# ATmega64A register map
Vendor: Atmel; File version: 1.0
CPU: other r0p0, little endian, no MPU, no FPU, 4 interrupt priority bits
Registers are 8-bit, read-write, reset 0x0 unless marked. A register's access mark holds for its fields unless they carry their own. Offsets are from the block's base; lines under a group give offsets from that group; [hi:lo] are bit positions; {n}, {i} and the like mark numbered series; 'fields as' and 'values as' point back to an identical list; <NAME> marks a mode.

## Memory map
0x00800000 FUSE size 0x3 — Fuses
0x00800000 LOCKBIT size 0x1 — Lockbits
0x00800020 PORTF blocks up to offset 0x43 — I/O Port
0x00800021 PORTE size 0x3 — I/O Port
0x00800024 ADC blocks up to offset 0x6B — Analog-to-Digital Converter
0x00800028 AC blocks up to offset 0x19 — Analog Comparator
0x00800029 USART0 blocks up to offset 0x6D — USART
0x0080002D SPI size 0x3 — Serial Peripheral Interface
0x00800030 PORTD size 0x3 — I/O Port
0x00800033 PORTC size 0x3 — I/O Port
0x00800036 PORTB size 0x3 — I/O Port
0x00800039 PORTA size 0x3 — I/O Port
0x0080003C EEPROM size 0x4
0x00800040 MISC size 0x1 — Other Registers
0x00800040 TC0 blocks up to offset 0x18 — Timer/Counter, 8-bit Async
0x00800040 TC1 blocks up to offset 0x3E — Timer/Counter, 16-bit
0x00800040 TC3 blocks up to offset 0x4D — Timer/Counter, 16-bit
0x00800041 WDT size 0x1 — Watchdog Timer
0x00800042 JTAG blocks up to offset 0x13 — JTAG Interface
0x00800043 TC2 blocks up to offset 0x15 — Timer/Counter, 8-bit
0x00800054 CPU blocks up to offset 0x1C — CPU Registers
0x00800058 EXINT blocks up to offset 0x13 — External Interrupts
0x00800063 PORTG size 0x3 — I/O Port
0x00800068 BOOT_LOAD size 0x1 — Bootloader
0x00800070 TWI size 0x5 — Two Wire Serial Interface
0x00800098 USART1 size 0x6 — USART

## Interrupts
0 RESET (CPU) — External Pin, Power-on Reset, Brown-out Reset, Watchdog Reset and JTAG AVR Reset
{n+1} INT{n} (CPU) (n=0..7) — External Interrupt Request {n}
9 TIMER2_COMP (CPU) — Timer/Counter2 Compare Match
10 TIMER2_OVF (CPU) — Timer/Counter2 Overflow
11 TIMER1_CAPT (CPU) — Timer/Counter1 Capture Event
12 TIMER1_COMPA (CPU) — Timer/Counter1 Compare Match A
13 TIMER1_COMPB (CPU) — Timer/Counter Compare Match B
14 TIMER1_OVF (CPU) — Timer/Counter1 Overflow
15 TIMER0_COMP (CPU) — Timer/Counter0 Compare Match
16 TIMER0_OVF (CPU) — Timer/Counter0 Overflow
17 SPI_STC (CPU) — SPI Serial Transfer Complete
18 USART0_RX (CPU) — USART0, Rx Complete
19 USART0_UDRE (CPU) — USART0 Data Register Empty
20 USART0_TX (CPU) — USART0, Tx Complete
21 ADC (CPU) — ADC Conversion Complete
22 EE_READY (CPU) — EEPROM Ready
23 ANALOG_COMP (CPU) — Analog Comparator
24 TIMER1_COMPC (CPU) — Timer/Counter1 Compare Match C
25 TIMER3_CAPT (CPU) — Timer/Counter3 Capture Event
26 TIMER3_COMPA (CPU) — Timer/Counter3 Compare Match A
27 TIMER3_COMPB (CPU) — Timer/Counter3 Compare Match B
28 TIMER3_COMPC (CPU) — Timer/Counter3 Compare Match C
29 TIMER3_OVF (CPU) — Timer/Counter3 Overflow
30 USART1_RX (CPU) — USART1, Rx Complete
31 USART1_UDRE (CPU) — USART1, Data Register Empty
32 USART1_TX (CPU) — USART1, Tx Complete
33 TWI (CPU) — 2-wire Serial Interface
34 SPM_READY (CPU) — Store Program Memory Read

## AC — Analog Comparator
Base 0x00800028
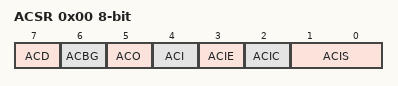
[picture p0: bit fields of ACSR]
0x00 ACSR — Analog Comparator Control And Status Register (read-only for debugger)
  [7] ACD — Analog Comparator Disable
  [6] ACBG — Analog Comparator Bandgap Select
  [5] ACO — Analog Compare Output
  [4] ACI — Analog Comparator Interrupt Flag
  [3] ACIE — Analog Comparator Interrupt Enable
  [2] ACIC — Analog Comparator Input Capture Enable
  [1:0] ACIS — Analog Comparator Interrupt Mode Select bits
    0=INTERRUPT_ON_TOGGLE; 2=INTERRUPT_ON_FALLING_EDGE; 3=INTERRUPT_ON_RISING_EDGE
0x18 SFIOR — Special Function IO Register
  [3] ACME — Analog Comparator Multiplexer Enable

## ADC — Analog-to-Digital Converter
Base 0x00800024
0x00 ADC 16-bit (reset mask 0xFF) — ADC Data Register Bytes
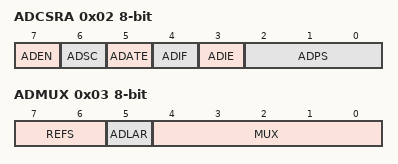
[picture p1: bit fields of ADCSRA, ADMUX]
0x02 ADCSRA — The ADC Control and Status register A (read-only for debugger)
  [7] ADEN — ADC Enable
  [6] ADSC — ADC Start Conversion
  [5] ADATE — ADC Auto Trigger Enable
  [4] ADIF — ADC Interrupt Flag
  [3] ADIE — ADC Interrupt Enable
  [2:0] ADPS — ADC Prescaler Select Bits
    1=2; 2=4; 3=8; 4=16; 5=32; 6=64; 7=128
0x03 ADMUX — The ADC multiplexer Selection Register
  [7:6] REFS — Reference Selection Bits
    0=AREF_INTERNAL_VREF_TURNED_OFF; 1=AVCC_WITH_EXTERNAL_CAPACITOR_AT_AREF_PIN; 3=INTERNAL_2_56V_VOLTAGE_REFERENCE_WITH_EXTERNAL_CAPACITOR_AT_AREF_PIN
  [5] ADLAR — Left Adjust Result
  [4:0] MUX — Analog Channel and Gain Selection Bits
0x6A ADCSRB — The ADC Control and Status register B
  [2:0] ADTS — ADC Auto Trigger Source bits
    0=FREE_RUNNING_MODE; 1=ANALOG_COMPARATOR; 2=EXTERNAL_INTERRUPT_REQUEST_0; 3=TIMER_COUNTER0_COMPARE_MATCH_A; 4=TIMER_COUNTER0_OVERFLOW; 5=TIMER_COUNTER1_COMPARE_MATCH_B; 6=TIMER_COUNTER1_OVERFLOW; 7=TIMER_COUNTER1_CAPTURE_EVENT
